# XMC4700 register map
Vendor: Infineon; File version: 1.0.3 (Reference Manual v1.0)
CPU: CM4 r2p0, little endian, MPU, FPU, 6 interrupt priority bits
Registers are 32-bit, read-write, reset 0x0 unless marked. A register's access mark holds for its fields unless they carry their own. Offsets are from the block's base; [hi:lo] are bit positions; {n}, {i} and the like mark numbered series; 'fields as' and 'values as' point back to an identical list.

## USIC0_CH0 — Universal Serial Interface Controller 0
Base 0x40030000
Same registers: USIC0_CH1 0x40030200, USIC1_CH0 0x48020000, USIC1_CH1 0x48020200, USIC2_CH0 0x48024000, USIC2_CH1 0x48024200
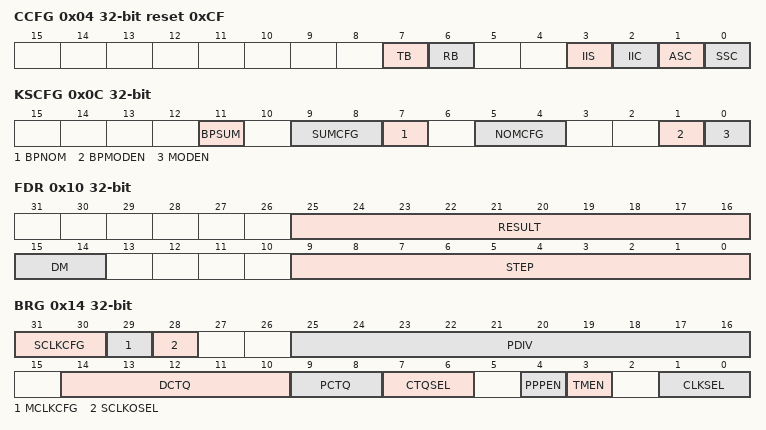
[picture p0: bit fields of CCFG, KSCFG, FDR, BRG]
0x04 CCFG ro reset 0xCF — Channel Configuration Register
  [7] TB — Transmit FIFO Buffer Available
    0=A transmit FIFO buffer is not available; 1=A transmit FIFO buffer is available
  [6] RB — Receive FIFO Buffer Available
    0=A receive FIFO buffer is not available; 1=A receive FIFO buffer is available
  [3] IIS — IIS Protocol Available
    0=The IIS protocol is not available; 1=The IIS protocol is available
  [2] IIC — IIC Protocol Available
    0=The IIC protocol is not available; 1=The IIC protocol is available
  [1] ASC — ASC Protocol Available
    0=The ASC protocol is not available; 1=The ASC protocol is available
  [0] SSC — SSC Protocol Available
    0=The SSC protocol is not available; 1=The SSC protocol is available
0x0C KSCFG access per field — Kernel State Configuration Register
  [11] BPSUM wo — Bit Protection for SUMCFG
    0=SUMCFG is not changed; 1=SUMCFG is updated with the written value
  [9:8] SUMCFG rw — Suspend Mode Configuration
  [7] BPNOM wo — Bit Protection for NOMCFG
    0=NOMCFG is not changed; 1=NOMCFG is updated with the written value
  [5:4] NOMCFG rw — Normal Operation Mode Configuration
    0=Run mode 0 is selected; 1=Run mode 1 is selected; 2=Stop mode 0 is selected; 3=Stop mode 1 is selected
  [1] BPMODEN wo — Bit Protection for MODEN
    0=MODEN is not changed; 1=MODEN is updated with the written value
  [0] MODEN rw — Module Enable
    0=The module is switched off immediately (without respecting a stop condition). It does not react on mode control actions and the module clock is switched off. The module does not react on read accesses and ignores write accesses (except to KSCFG).; 1=The module is switched on and can operate. After writing 1 to MODEN, it is recommended to read register KSCFG to avoid pipeline effects in the control block before accessing other Service Request Processing registers.
0x10 FDR access per field — Fractional Divider Register
  [25:16] RESULT ro — Result Value
  [15:14] DM rw — Divider Mode
    0=The divider is switched off, fFD = 0; 1=Normal divider mode selected; 2=Fractional divider mode selected; 3=The divider is switched off, fFD = 0
  [9:0] STEP rw — Step Value
0x14 BRG — Baud Rate Generator Register
  [31:30] SCLKCFG — Shift Clock Output Configuration
    0=The passive level is 0 and the delay is disabled; 1=The passive level is 1 and the delay is disabled; 2=The passive level is 0 and the delay is enabled; 3=The passive level is 1 and the delay is enabled
  [29] MCLKCFG — Master Clock Configuration
    0=The passive level is 0; 1=The passive level is 1
  [28] SCLKOSEL — Shift Clock Output Select
    0=SCLK from the baud rate generator is selected as the SCLKOUT input source; 1=The transmit shift clock from DX1 input stage is selected as the SCLKOUT input source
  [25:16] PDIV — Divider Mode: Divider Factor to Generate fPDIV
  [14:10] DCTQ — Denominator for Time Quanta Counter
  [9:8] PCTQ — Pre-Divider for Time Quanta Counter
  [7:6] CTQSEL — Input Selection for CTQ
    0=fCTQIN = fPDIV; 1=fCTQIN = fPPP; 2=fCTQIN = fSCLK; 3=fCTQIN = fMCLK
  [4] PPPEN — Enable 2:1 Divider for fPPP
    0=The 2:1 divider for fPPP is disabled. fPPP = fPIN; 1=The 2:1 divider for fPPP is enabled. fPPP = fMCLK = fPIN / 2.
  [3] TMEN — Timing Measurement Enable
    0=Timing measurement is disabled: The trigger signals DX0T and DX1T are ignored; 1=Timing measurement is enabled: The 10-bit counter is incremented by 1 with fPPP and stops counting when reaching its maximum value. If one of the trigger signals DX0T or DX1T become active, the counter value is captured into bit field CTV, the counter is cleared and a transmit shift event is generated.
  [1:0] CLKSEL — Clock Selection
    0=The fractional divider frequency fFD is selected; 2=The trigger signal DX1T defines fPIN. Signal MCLK toggles with fPIN.; 3=Signal MCLK corresponds to the DX1S signal and the frequency fPIN is derived from the rising edges of DX1S
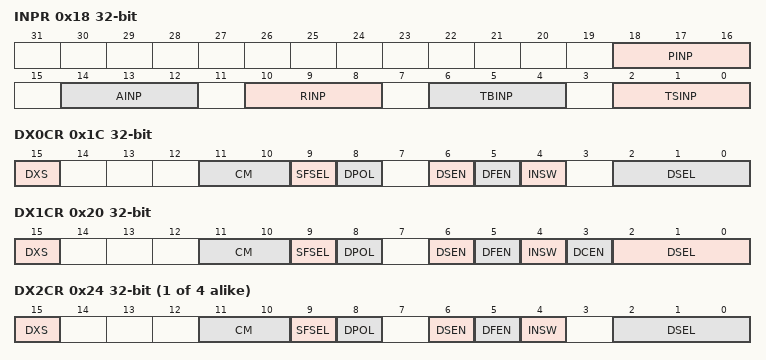
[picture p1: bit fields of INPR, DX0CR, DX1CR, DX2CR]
0x18 INPR — Interrupt Node Pointer Register
  [18:16] PINP — Transmit Shift Interrupt Node Pointer
  [14:12] AINP — Alternative Receive Interrupt Node Pointer
  [10:8] RINP — Receive Interrupt Node Pointer
  [6:4] TBINP — Transmit Buffer Interrupt Node Pointer
  [2:0] TSINP — Transmit Shift Interrupt Node Pointer
    {v}=Output SR{v} becomes activated (v=0..5)
0x1C DX0CR access per field — Input Control Register 0
  [15] DXS ro — Synchronized Data Value
    0=The current value of DXnS is 0; 1=The current value of DXnS is 1
  [11:10] CM rw — Combination Mode
    0=The trigger activation is disabled; 1=A rising edge activates DXnT; 2=A falling edge activates DXnT; 3=Both edges activate DXnT
  [9] SFSEL rw — Sampling Frequency Selection
    0=The sampling frequency is fPB; 1=The sampling frequency is fFD
  [8] DPOL rw — Data Polarity for DXn
    0=The input signal is not inverted; 1=The input signal is inverted
  [6] DSEN rw — Data Synchronization Enable
    0=The un-synchronized signal can be taken as input for the data shift unit; 1=The synchronized signal can be taken as input for the data shift unit
  [5] DFEN rw — Digital Filter Enable
    0=The input signal is not digitally filtered; 1=The input signal is digitally filtered
  [4] INSW rw — Input Switch
    0=The input of the data shift unit is controlled by the protocol pre-processor; 1=The input of the data shift unit is connected to the selected data input line. This setting is used if the signals are directly derived from an input pin without treatment by the protocol pre-processor.
  [2:0] DSEL rw — Data Selection for Input Signal
    0=The data input DXnA is selected; 1=The data input DXnB is selected; 2=The data input DXnC is selected; 3=The data input DXnD is selected; 4=The data input DXnE is selected; 5=The data input DXnF is selected; 6=The data input DXnG is selected; 7=The data input is always 1
0x20 DX1CR access per field — Input Control Register 1
  [15] DXS ro — Synchronized Data Value
    0=The current value of DX1S is 0; 1=The current value of DX1S is 1
  [11:10] CM rw — Combination Mode
    0=The trigger activation is disabled; 1=A rising edge activates DX1T; 2=A falling edge activates DX1T; 3=Both edges activate DX1T
  [9] SFSEL rw — Sampling Frequency Selection
    values as DX0CR.SFSEL
  [8] DPOL rw — Data Polarity for DXn
    values as DX0CR.DPOL
  [6] DSEN rw — Data Synchronization Enable
    values as DX0CR.DSEN
  [5] DFEN rw — Digital Filter Enable
    values as DX0CR.DFEN
  [4] INSW rw — Input Switch
    values as DX0CR.INSW
  [3] DCEN rw — Delay Compensation Enable
    0=The receive shift clock is dependent on INSW selection; 1=The receive shift clock is connected to the selected data input line. This setting is used if delay compensation is required in SSC and IIS protocols, else DCEN should always be 0.
  [2:0] DSEL rw — Data Selection for Input Signal
    0=The data input DX1A is selected; 1=The data input DX1B is selected; 2=The data input DX1C is selected; 3=The data input DX1D is selected; 4=The data input DX1E is selected; 5=The data input DX1F is selected; 6=The data input DX1G is selected; 7=The data input is always 1
{0x1C+4i} DX{i}CR access per field (i=2..5) — Input Control Register {i}
  fields as DX0CR
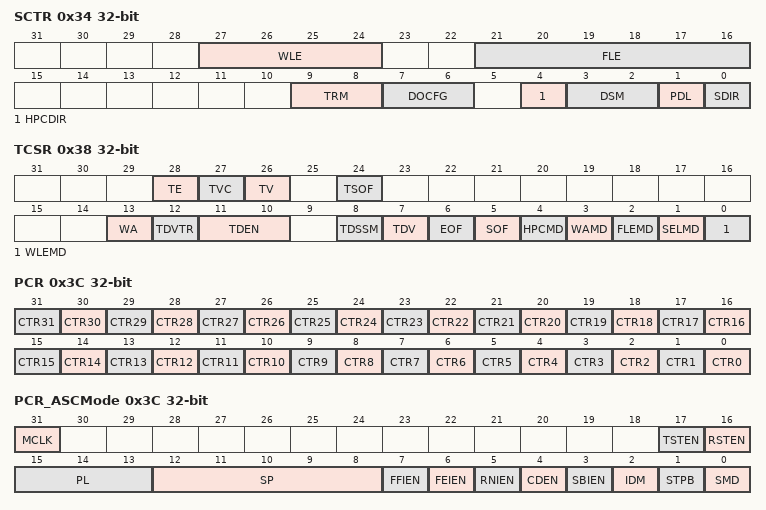
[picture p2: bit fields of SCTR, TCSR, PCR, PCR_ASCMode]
0x34 SCTR — Shift Control Register
  [27:24] WLE — Word Length
    0=The data word contains 1 data bit located at bit position 0; 1=The data word contains 2 data bits located at bit positions [1:0]; 14=The data word contains 15 data bits located at bit positions [14:0]; 15=The data word contains 16 data bits located at bit positions [15:0]
  [21:16] FLE — Frame Length
  [9:8] TRM — Transmission Mode
    0=The shift control signal is considered as inactive and data frame transfers are not possible; 1=The shift control signal is considered active if it is at 1-level. This is the setting to be programmed to allow data transfers.; 2=The shift control signal is considered active if it is at 0-level. It is recommended to avoid this setting and to use the inversion in the DX2 stage in case of a low-active signal.; 3=The shift control signal is considered active without referring to the actual signal level. Data frame transfer is possible after each edge of the signal.
  [7:6] DOCFG — Data Output Configuration
    0=DOUTx = shift data value; 1=DOUTx = inverted shift data value
  [4] HPCDIR — Port Control Direction
    0=The pin(s) with hardware pin control enabled are selected to be in input mode; 1=The pin(s) with hardware pin control enabled are selected to be in output mode
  [3:2] DSM — Data Shift Mode
    0=Receive and transmit data is shifted in and out one bit at a time through DX0 and DOUT0; 2=Receive and transmit data is shifted in and out two bits at a time through two input stages (DX0 and DX3) and DOUT[1:0] respectively; 3=Receive and transmit data is shifted in and out four bits at a time through four input stages (DX0, DX[5:3]) and DOUT[3:0] respectively
  [1] PDL — Passive Data Level
    0=The passive data level is 0; 1=The passive data level is 1
  [0] SDIR — Shift Direction
    0=Shift LSB first. The first data bit of a data word is located at bit position 0.; 1=Shift MSB first. The first data bit of a data word is located at the bit position given by bit field SCTR.WLE.
0x38 TCSR access per field — Transmit Control/Status Register
  [28] TE ro — Trigger Event
    0=The trigger event has not yet been detected. A transmission of the data word in TBUF can not be started.; 1=The trigger event has been detected (or the trigger mechanism is switched off) and a transmission of the data word in TBUF can not be started
  [27] TVC ro — Transmission Valid Cumulated
    0=Since TVC has been set, at least one data buffer underflow condition has occurred; 1=Since TVC has been set, no data buffer underflow condition has occurred
  [26] TV ro — Transmission Valid
    0=The latest start of a data word transmission has taken place while no valid data was available. As a result, the transmission of a data words with passive level (SCTR.PDL) has been started.; 1=The latest start of a data word transmission has taken place with valid data from TBUF
  [24] TSOF ro — Transmitted Start Of Frame
    0=The latest data word transmission has not been started for the first word of a data frame; 1=The latest data word transmission has been started for the first word of a data frame
  [13] WA rw — Word Address
    0=The data word in TBUF will be transmitted after a falling edge of WA has been detected (referring to PSR.WA); 1=The data word in TBUF will be transmitted after a rising edge of WA has been detected (referring to PSR.WA)
  [12] TDVTR rw — TBUF Data Valid Trigger
    0=Bit TCSR.TE is permanently set; 1=Bit TCSR.TE is set if DX2T becomes active while TDV = 1
  [11:10] TDEN rw — TBUF Data Enable
    0=A transmission start of the data word in TBUF is disabled. If a transmission is started, the passive data level is sent out.; 1=A transmission of the data word in TBUF can be started if TDV = 1; 2=A transmission of the data word in TBUF can be started if TDV = 1 while DX2S = 0; 3=A transmission of the data word in TBUF can be started if TDV = 1 while DX2S = 1
  [8] TDSSM rw — TBUF Data Single Shot Mode
    0=The data word in TBUF is not considered as invalid after it has been loaded into the transmit shift register. The loading of the TBUF data into the shift register does not clear TDV.; 1=The data word in TBUF is considered as invalid after it has been loaded into the shift register. In ASC and IIC mode, TDV is cleared with the TBI event, whereas in SSC and IIS mode, it is cleared with the RSI event. TDSSM = 1 has to be programmed if an optional data buffer is used.
  [7] TDV ro — Transmit Data Valid
    0=The data word in TBUF is not valid for transmission; 1=The data word in TBUF is valid for transmission and a transmission start is possible. New data should not be written to a TBUFx input location while TDV = 1.
  [6] EOF rw — End Of Frame
    0=The data word in TBUF is not considered as last word of an SSC frame; 1=The data word in TBUF is considered as last word of an SSC frame
  [5] SOF rw — Start Of Frame
    0=The data word in TBUF is not considered as first word of a frame; 1=The data word in TBUF is considered as first word of a frame. A currently running frame is finished and MSLS becomes deactivated (respecting the programmed delays).
  [4] HPCMD rw — Hardware Port Control Mode
    0=The automatic update of bits SCTR.DSM and SCTR.HPCDIR is disabled; 1=The automatic update of bits SCTR.DSM and SCTR.HPCDIR is enabled
  [3] WAMD rw — WA Mode
    0=The automatic update of bit WA is disabled; 1=The automatic update of bit WA is enabled
  [2] FLEMD rw — FLE Mode
    0=The automatic update of FLE is disabled; 1=The automatic update of FLE is enabled
  [1] SELMD rw — Select Mode
    0=The automatic update of PCR.CTR[23:16] is disabled; 1=The automatic update of PCR.CTR[23:16] is disabled
  [0] WLEMD rw — WLE Mode
    0=The automatic update of SCTR.WLE and TCSR.EOF is disabled; 1=The automatic update of SCTR.WLE and TCSR.EOF is enabled
0x3C PCR — Protocol Control Register
  [n] CTR{n} (n=0..31) — Protocol Control Bit {n}
0x3C PCR_ASCMode (alternate view of PCR) — Protocol Control Register [ASC Mode]
  [31] MCLK — Master Clock Enable
    0=The MCLK generation is disabled and the MCLK signal is 0; 1=The MCLK generation is enabled
  [17] TSTEN — Transmitter Status Enable
    0=Flag PSR[9] is not modified depending on the transmitter status; 1=Flag PSR[9] is set during the complete transmission of a frame
  [16] RSTEN — Receiver Status Enable
    0=Flag PSR[9] is not modified depending on the receiver status; 1=Flag PSR[9] is set during the complete reception of a frame
  [15:13] PL — Pulse Length
    0=The pulse length is equal to the bit length (no shortened 0); 1=The pulse length of a 0 bit is 2 time quanta; 2=The pulse length of a 0 bit is 3 time quanta; 7=The pulse length of a 0 bit is 8 time quanta
  [12:8] SP — Sample Point
  [7] FFIEN — Frame Finished Interrupt Enable
    0=The interrupt generation is disabled; 1=The interrupt generation is enabled
  [6] FEIEN — Format Error Interrupt Enable
    values as FFIEN
  [5] RNIEN — Receiver Noise Detection Interrupt Enable
    values as FFIEN
  [4] CDEN — Collision Detection Enable
    0=The collision detection is disabled; 1=If a collision is detected, the transmitter stops its data transmission, outputs a 1, sets bit PSR.COL and generates a protocol interrupt. In order to allow data transmission again, PSR.COL has to be cleared by software.
  [3] SBIEN — Synchronization Break Interrupt Enable
    values as FFIEN
  [2] IDM — Idle Detection Mode
    0=The bus idle detection is switched off and bits PSR.TXIDLE and PSR.RXIDLE are set automatically to enable data transfers without checking the inputs before; 1=The bus is considered as idle after a number of consecutive passive bit times defined by SCTR.FLE plus 2 (in the case without parity bit) or plus 3 (in the case with parity bit)
  [1] STPB — Stop Bits
    0=The number of stop bits is 1; 1=The number of stop bits is 2
  [0] SMD — Sample Mode
    0=Only one sample is taken per bit time. The current input value is sampled.; 1=Three samples are taken per bit time and a majority decision is made
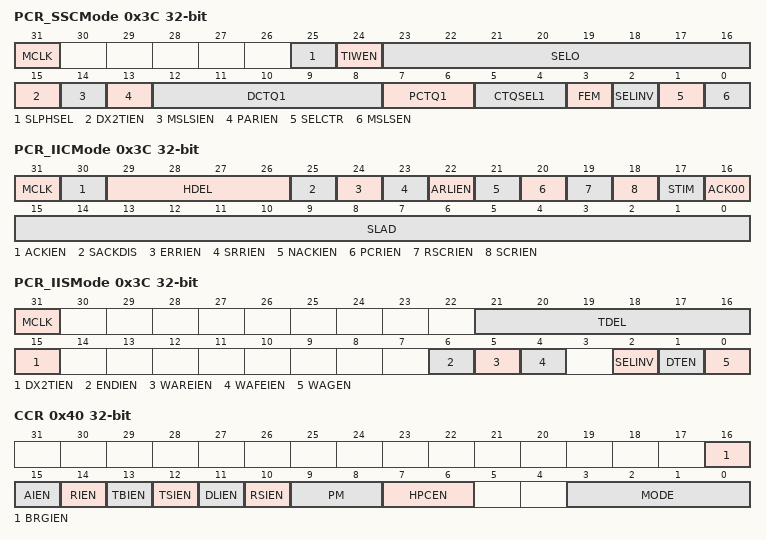
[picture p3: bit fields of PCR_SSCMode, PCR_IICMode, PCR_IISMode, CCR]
0x3C PCR_SSCMode (alternate view of PCR) — Protocol Control Register [SSC Mode]
  [31] MCLK — Master Clock Enable
    0=The MCLK generation is disabled and output MCLK = 0; 1=The MCLK generation is enabled
  [25] SLPHSEL — Slave Mode Clock Phase Select
    0=Data bits are shifted out with the leading edge of the shift clock signal and latched in with the trailing edge; 1=The first data bit is shifted out when the data shift unit receives a low to high transition from the DX2 stage. Subsequent bits are shifted out with the trailing edge of the shift clock signal. Data bits are always latched in with the leading edge.
  [24] TIWEN — Enable Inter-Word Delay Tiw
    0=No delay between data words of the same frame; 1=The inter-word delay Tiw is enabled and introduced between data words of the same frame
  [23:16] SELO — Select Output
    0=The corresponding SELOx line cannot be activated; 1=The corresponding SELOx line can be activated (according to the mode selected by SELCTR)
  [15] DX2TIEN — DX2T Interrupt Enable
    0=A protocol interrupt is not generated if DX2T is activated; 1=A protocol interrupt is generated if DX2T is activated
  [14] MSLSIEN — MSLS Interrupt Enable
    0=A protocol interrupt is not generated if a change of signal MSLS is detected; 1=A protocol interrupt is generated if a change of signal MSLS is detected
  [13] PARIEN — Parity Error Interrupt Enable
    0=A protocol interrupt is not generated with the detection of a parity error; 1=A protocol interrupt is generated with the detection of a parity error
  [12:8] DCTQ1 — Divider Factor DCTQ1 for Tiw and Tnf
  [7:6] PCTQ1 — Divider Factor PCTQ1 for Tiw and Tnf
  [5:4] CTQSEL1 — Input Frequency Selection
    values as BRG.CTQSEL
  [3] FEM — Frame End Mode
    0=The current data frame is considered as finished when the last bit of a data word has been sent out and the transmit buffer TBUF does not contain new data (TDV = 0); 1=The MSLS signal is kept active also while no new data is available and no other end of frame condition is reached. In this case, the software can accept delays in delivering the data without automatic deactivation of MSLS in multi-word data frames.
  [2] SELINV — Select Inversion
    0=The SELO outputs have the same polarity as the MSLS signal (active high); 1=The SELO outputs have the inverted polarity to the MSLS signal (active low)
  [1] SELCTR — Select Control
    0=The coded select mode is enabled; 1=The direct select mode is enabled
  [0] MSLSEN — MSLS Enable
    0=The MSLS generation is disabled (MSLS = 0). This is the setting for SSC slave mode.; 1=The MSLS generation is enabled. This is the setting for SSC master mode.
0x3C PCR_IICMode (alternate view of PCR) — Protocol Control Register [IIC Mode]
  [31] MCLK — Master Clock Enable
    0=The MCLK generation is disabled and MCLK is 0; 1=The MCLK generation is enabled
  [30] ACKIEN — Acknowledge Interrupt Enable
    0=The acknowledge interrupt is disabled; 1=The acknowledge interrupt is enabled
  [29:26] HDEL — Hardware Delay
  [25] SACKDIS — Slave Acknowledge Disable
    0=The generation of an active slave acknowledge is enabled (slave acknowledge with 0 level = more bytes can be received); 1=The generation of an active slave acknowledge is disabled (slave acknowledge with 1 level = reception stopped)
  [24] ERRIEN — Error Interrupt Enable
    0=The error interrupt is disabled; 1=The error interrupt is enabled
  [23] SRRIEN — Slave Read Request Interrupt Enable
    0=The slave read request interrupt is disabled; 1=The slave read request interrupt is enabled
  [22] ARLIEN — Arbitration Lost Interrupt Enable
    0=The arbitration lost interrupt is disabled; 1=The arbitration lost interrupt is enabled
  [21] NACKIEN — Non-Acknowledge Interrupt Enable
    0=The non-acknowledge interrupt is disabled; 1=The non-acknowledge interrupt is enabled
  [20] PCRIEN — Stop Condition Received Interrupt Enable
    0=The stop condition interrupt is disabled; 1=The stop condition interrupt is enabled
  [19] RSCRIEN — Repeated Start Condition Received Interrupt Enable
    0=The repeated start condition interrupt is disabled; 1=The repeated start condition interrupt is enabled
  [18] SCRIEN — Start Condition Received Interrupt Enable
    0=The start condition interrupt is disabled; 1=The start condition interrupt is enabled
  [17] STIM — Symbol Timing
    0=A symbol contains 10 time quanta. The timing is adapted for standard mode (100 kBaud).; 1=A symbol contains 25 time quanta. The timing is adapted for fast mode (400 kBaud).
  [16] ACK00 — Acknowledge 00H
    0=The slave device is not sensitive to this address; 1=The slave device is sensitive to this address
  [15:0] SLAD — Slave Address
0x3C PCR_IISMode (alternate view of PCR) — Protocol Control Register [IIS Mode]
  [31] MCLK — Master Clock Enable
    values as PCR_IICMode.MCLK
  [21:16] TDEL — Transfer Delay
  [15] DX2TIEN — DX2T Interrupt Enable
    0=A protocol interrupt is not generated if DX2T is active; 1=A protocol interrupt is generated if DX2T is active
  [6] ENDIEN — END Interrupt Enable
    0=A protocol interrupt is not activated; 1=A protocol interrupt is activated
  [5] WAREIEN — WA Rising Edge Interrupt Enable
    0=A protocol interrupt is not activated if a rising edge of WA is generated; 1=A protocol interrupt is activated if a rising edge of WA is generated
  [4] WAFEIEN — WA Falling Edge Interrupt Enable
    0=A protocol interrupt is not activated if a falling edge of WA is generated; 1=A protocol interrupt is activated if a falling edge of WA is generated
  [2] SELINV — Select Inversion
    0=The SELOx outputs have the same polarity as the WA signal; 1=The SELOx outputs have the inverted polarity to the WA signal
  [1] DTEN — Data Transfers Enable
    0=The changes of the WA input signal are ignored and no transfers take place; 1=Transfers are enabled
  [0] WAGEN — WA Generation Enable
    0=The IIS can be used as slave. The generation of the word address signal is disabled. The output signal WA is 0. The MCLKO signal generation depends on PCR.MCLK.; 1=The IIS can be used as master. The generation of the word address signal is enabled. The signal starts with a 0 after being enabled. The generation of MCLK is enabled, independent of PCR.MCLK. After clearing WAGEN, the USIC module stops the generation of the WA signal within the next 4 WA periods.
0x40 CCR — Channel Control Register
  [16] BRGIEN — Baud Rate Generator Interrupt Enable
    0=The baud rate generator interrupt is disabled; 1=The baud rate generator interrupt is enabled. In case of a baud rate generator event, the service request output SRx indicated by INPR.PINP is activated.
  [15] AIEN — Alternative Receive Interrupt Enable
    0=The alternative receive interrupt is disabled; 1=The alternative receive interrupt is enabled. In case of an alternative receive event, the service request output SRx indicated by INPR.AINP is activated.
  [14] RIEN — Receive Interrupt Enable
    0=The receive interrupt is disabled; 1=The receive interrupt is enabled. In case of a receive event, the service request output SRx indicated by INPR.RINP is activated.
  [13] TBIEN — Transmit Buffer Interrupt Enable
    0=The transmit buffer interrupt is disabled; 1=The transmit buffer interrupt is enabled. In case of a transmit buffer event, the service request output SRx indicated by INPR.TBINP is activated.
  [12] TSIEN — Transmit Shift Interrupt Enable
    0=The transmit shift interrupt is disabled; 1=The transmit shift interrupt is enabled. In case of a transmit shift interrupt event, the service request output SRx indicated by INPR.TSINP is activated.
  [11] DLIEN — Data Lost Interrupt Enable
    0=The data lost interrupt is disabled; 1=The data lost interrupt is enabled. In case of a data lost event, the service request output SRx indicated by INPR.PINP is activated.
  [10] RSIEN — Receiver Start Interrupt Enable
    0=The receiver start interrupt is disabled; 1=The receiver start interrupt is enabled. In case of a receiver start event, the service request output SRx indicated by INPR.TBINP is activated.
  [9:8] PM — Parity Mode
    0=The parity generation is disabled; 2=Even parity is selected (parity bit = 1 on odd number of 1s in data, parity bit = 0 on even number of 1s in data); 3=Odd parity is selected (parity bit = 0 on odd number of 1s in data, parity bit = 1 on even number of 1s in data)
  [7:6] HPCEN — Hardware Port Control Enable
    0=The hardware port control is disabled; 1=The hardware port control is enabled for DX0 and DOUT0; 2=The hardware port control is enabled for DX3, DX0 and DOUT[1:0]; 3=The hardware port control is enabled for DX0, DX[5:3] and DOUT[3:0]
  [3:0] MODE — Operating Mode
    0=The USIC channel is disabled. All protocol-related state machines are set to an idle state.; 1=The SSC (SPI) protocol is selected; 2=The ASC (SCI, UART) protocol is selected; 3=The IIS protocol is selected; 4=The IIC protocol is selected
0x44 CMTR — Capture Mode Timer Register
  [9:0] CTV — Captured Timer Value
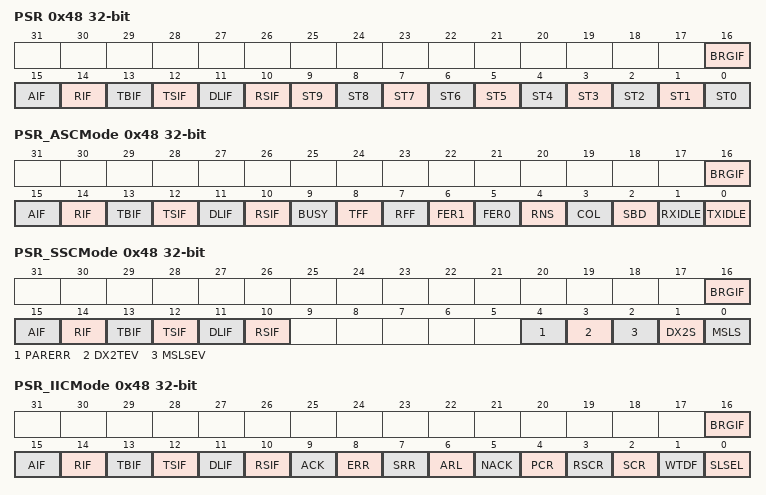
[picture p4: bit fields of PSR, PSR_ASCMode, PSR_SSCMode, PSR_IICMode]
0x48 PSR — Protocol Status Register
  [16] BRGIF — Baud Rate Generator Indication Flag
    0=A baud rate generator event has not occurred; 1=A baud rate generator event has occurred
  [15] AIF — Alternative Receive Indication Flag
    0=An alternative receive event has not occurred; 1=An alternative receive event has occurred
  [14] RIF — Receive Indication Flag
    0=A receive event has not occurred; 1=A receive event has occurred
  [13] TBIF — Transmit Buffer Indication Flag
    0=A transmit buffer event has not occurred; 1=A transmit buffer event has occurred
  [12] TSIF — Transmit Shift Indication Flag
    0=A transmit shift event has not occurred; 1=A transmit shift event has occurred
  [11] DLIF — Data Lost Indication Flag
    0=A data lost event has not occurred; 1=A data lost event has occurred
  [10] RSIF — Receiver Start Indication Flag
    0=A receiver start event has not occurred; 1=A receiver start event has occurred
  [n] ST{n} (n=0..9) — Protocol Status Flag {n}
0x48 PSR_ASCMode access per field (alternate view of PSR) — Protocol Status Register [ASC Mode]
  [16] BRGIF rw — Baud Rate Generator Indication Flag
    values as PSR.BRGIF
  [15] AIF rw — Alternative Receive Indication Flag
    values as PSR.AIF
  [14] RIF rw — Receive Indication Flag
    values as PSR.RIF
  [13] TBIF rw — Transmit Buffer Indication Flag
    values as PSR.TBIF
  [12] TSIF rw — Transmit Shift Indication Flag
    values as PSR.TSIF
  [11] DLIF rw — Data Lost Indication Flag
    values as PSR.DLIF
  [10] RSIF rw — Receiver Start Indication Flag
    values as PSR.RSIF
  [9] BUSY ro — Transfer Status BUSY
    0=A data transfer does not take place; 1=A data transfer currently takes place
  [8] TFF rw — Transmitter Frame Finished
    0=The transmitter frame is not yet finished; 1=The transmitter frame is finished
  [7] RFF rw — Receive Frame Finished
    0=The received frame is not yet finished; 1=The received frame is finished
  [6] FER1 rw — Format Error in Stop Bit 1
    0=A format error 1 has not been detected; 1=A format error 1 has been detected
  [5] FER0 rw — Format Error in Stop Bit 0
    0=A format error 0 has not been detected; 1=A format error 0 has been detected
  [4] RNS rw — Receiver Noise Detected
    0=Receiver noise has not been detected; 1=Receiver noise has been detected
  [3] COL rw — Collision Detected
    0=A collision has not yet been detected and frame transmission is possible; 1=A collision has been detected and frame transmission is not possible
  [2] SBD rw — Synchronization Break Detected
    0=A synchronization break has not yet been detected; 1=A synchronization break has been detected
  [1] RXIDLE rw — Reception Idle
    0=The receiver line has not yet been idle; 1=The receiver line has been idle and frame reception is possible
  [0] TXIDLE rw — Transmission Idle
    0=The transmitter line has not yet been idle; 1=The transmitter line has been idle and frame transmission is possible
0x48 PSR_SSCMode (alternate view of PSR) — Protocol Status Register [SSC Mode]
  [16] BRGIF — Baud Rate Generator Indication Flag
    values as PSR.BRGIF
  [15] AIF — Alternative Receive Indication Flag
    values as PSR.AIF
  [14] RIF — Receive Indication Flag
    values as PSR.RIF
  [13] TBIF — Transmit Buffer Indication Flag
    values as PSR.TBIF
  [12] TSIF — Transmit Shift Indication Flag
    values as PSR.TSIF
  [11] DLIF — Data Lost Indication Flag
    values as PSR.DLIF
  [10] RSIF — Receiver Start Indication Flag
    values as PSR.RSIF
  [4] PARERR — Parity Error Event Detected
    0=A parity error event has not been activated; 1=A parity error event has been activated
  [3] DX2TEV — DX2T Event Detected
    0=The DX2T signal has not been activated; 1=The DX2T signal has been activated
  [2] MSLSEV — MSLS Event Detected
    0=The MSLS signal has not changed its state; 1=The MSLS signal has changed its state
  [1] DX2S — DX2S Status
    0=DX2S is 0; 1=DX2S is 1
  [0] MSLS — MSLS Status
    0=The internal signal MSLS is inactive (0); 1=The internal signal MSLS is active (1)
0x48 PSR_IICMode (alternate view of PSR) — Protocol Status Register [IIC Mode]
  [16] BRGIF — Baud Rate Generator Indication Flag
    values as PSR.BRGIF
  [15] AIF — Alternative Receive Indication Flag
    values as PSR.AIF
  [14] RIF — Receive Indication Flag
    values as PSR.RIF
  [13] TBIF — Transmit Buffer Indication Flag
    values as PSR.TBIF
  [12] TSIF — Transmit Shift Indication Flag
    values as PSR.TSIF
  [11] DLIF — Data Lost Indication Flag
    values as PSR.DLIF
  [10] RSIF — Receiver Start Indication Flag
    values as PSR.RSIF
  [9] ACK — Acknowledge Received
    0=An acknowledge has not been received; 1=An acknowledge has been received
  [8] ERR — Error
    0=An IIC error has not been detected; 1=An IIC error has been detected
  [7] SRR — Slave Read Request
    0=A slave read request has not been detected; 1=A slave read request has been detected
  [6] ARL — Arbitration Lost
    0=An arbitration has not been lost; 1=An arbitration has been lost
  [5] NACK — Non-Acknowledge Received
    0=A non-acknowledge has not been received; 1=A non-acknowledge has been received
  [4] PCR — Stop Condition Received
    0=A stop condition has not yet been detected; 1=A stop condition has been detected
  [3] RSCR — Repeated Start Condition Received
    0=A repeated start condition has not yet been detected; 1=A repeated start condition has been detected
  [2] SCR — Start Condition Received
    0=A start condition has not yet been detected; 1=A start condition has been detected
  [1] WTDF — Wrong TDF Code Found
    0=A wrong TDF code has not been found; 1=A wrong TDF code has been found
  [0] SLSEL — Slave Select
    0=The device is not selected as slave; 1=The device is selected as slave
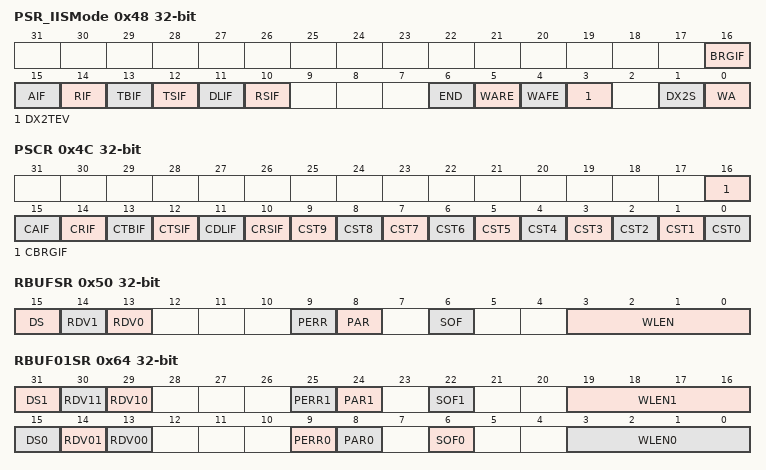
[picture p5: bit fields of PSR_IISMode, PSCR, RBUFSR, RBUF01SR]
0x48 PSR_IISMode (alternate view of PSR) — Protocol Status Register [IIS Mode]
  [16] BRGIF — Baud Rate Generator Indication Flag
    values as PSR.BRGIF
  [15] AIF — Alternative Receive Indication Flag
    values as PSR.AIF
  [14] RIF — Receive Indication Flag
    values as PSR.RIF
  [13] TBIF — Transmit Buffer Indication Flag
    values as PSR.TBIF
  [12] TSIF — Transmit Shift Indication Flag
    values as PSR.TSIF
  [11] DLIF — Data Lost Indication Flag
    values as PSR.DLIF
  [10] RSIF — Receiver Start Indication Flag
    values as PSR.RSIF
  [6] END — WA Generation End
    0=The WA generation has not yet ended (if it is running and WAGEN has been cleared); 1=The WA generation has ended (if it has been running)
  [5] WARE — WA Rising Edge Event
    0=A WA rising edge has not been generated; 1=A WA rising edge has been generated
  [4] WAFE — WA Falling Edge Event
    0=A WA falling edge has not been generated; 1=A WA falling edge has been generated
  [3] DX2TEV — DX2T Event Detected
    values as PSR_SSCMode.DX2TEV
  [1] DX2S — DX2S Status
    0=DX2S is 0; 1=DX2S is 1
  [0] WA — Word Address
    0=WA has been sampled 0; 1=WA has been sampled 1
0x4C PSCR wo — Protocol Status Clear Register
  [16] CBRGIF — Clear Baud Rate Generator Indication Flag
    0=No action; 1=Flag PSR.BRGIF is cleared
  [15] CAIF — Clear Alternative Receive Indication Flag
    0=No action; 1=Flag PSR.AIF is cleared
  [14] CRIF — Clear Receive Indication Flag
    0=No action; 1=Flag PSR.RIF is cleared
  [13] CTBIF — Clear Transmit Buffer Indication Flag
    0=No action; 1=Flag PSR.TBIF is cleared
  [12] CTSIF — Clear Transmit Shift Indication Flag
    0=No action; 1=Flag PSR.TSIF is cleared
  [11] CDLIF — Clear Data Lost Indication Flag
    0=No action; 1=Flag PSR.DLIF is cleared
  [10] CRSIF — Clear Receiver Start Indication Flag
    0=No action; 1=Flag PSR.RSIF is cleared
  [n] CST{n} (n=0..9) — Clear Status Flag {n} in PSR
    0=No action; 1=Flag PSR.STx is cleared
0x50 RBUFSR ro — Receiver Buffer Status Register
  [15] DS — Data Source of RBUF or RBUFD
  [14] RDV1 — Receive Data Valid in RBUF or RBUFD
  [13] RDV0 — Receive Data Valid in RBUF or RBUFD
  [9] PERR — Protocol-related Error in RBUF or RBUFD
  [8] PAR — Protocol-Related Argument in RBUF or RBUFD
  [6] SOF — Start of Frame in RBUF or RBUFD
  [3:0] WLEN — Received Data Word Length in RBUF or RBUFD
0x54 RBUF ro read-has-side-effects — Receiver Buffer Register
  [15:0] DSR — Received Data
0x58 RBUFD ro — Receiver Buffer Register for Debugger
  [15:0] DSR — Data from Shift Register
0x5C RBUF0 ro — Receiver Buffer Register 0
  [15:0] DSR0 — Data of Shift Registers 0[3:0]
0x60 RBUF1 ro — Receiver Buffer Register 1
  [15:0] DSR1 — Data of Shift Registers 1[3:0]
0x64 RBUF01SR ro — Receiver Buffer 01 Status Register
  [31] DS1 — Data Source
    0=The register RBUF contains the data of RBUF0 (same for associated status information); 1=The register RBUF contains the data of RBUF1 (same for associated status information)
  [30] RDV11 — Receive Data Valid in RBUF1
    0=Register RBUF1 does not contain data that has not yet been read out; 1=Register RBUF1 contains data that has not yet been read out
  [29] RDV10 — Receive Data Valid in RBUF0
    0=Register RBUF0 does not contain data that has not yet been read out; 1=Register RBUF0 contains data that has not yet been read out
  [25] PERR1 — Protocol-related Error in RBUF1
    0=The received protocol-related argument PAR matches the expected value. The reception of the data word sets bit PSR.RIF and can generate a receive interrupt.; 1=The received protocol-related argument PAR does not match the expected value. The reception of the data word sets bit PSR.AIF and can generate an alternative receive interrupt.
  [24] PAR1 — Protocol-Related Argument in RBUF1
  [22] SOF1 — Start of Frame in RBUF1
    0=The data in RBUF1 has not been the first data word of a data frame; 1=The data in RBUF1 has been the first data word of a data frame
  [19:16] WLEN1 — Received Data Word Length in RBUF1
    0=One bit has been received; 15=Sixteen bits have been received
  [15] DS0 — Data Source
    values as DS1
  [14] RDV01 — Receive Data Valid in RBUF1
    values as RDV11
  [13] RDV00 — Receive Data Valid in RBUF0
    values as RDV10
  [9] PERR0 — Protocol-related Error in RBUF0
    values as PERR1
  [8] PAR0 — Protocol-Related Argument in RBUF0
  [6] SOF0 — Start of Frame in RBUF0
    0=The data in RBUF0 has not been the first data word of a data frame; 1=The data in RBUF0 has been the first data word of a data frame
  [3:0] WLEN0 — Received Data Word Length in RBUF0
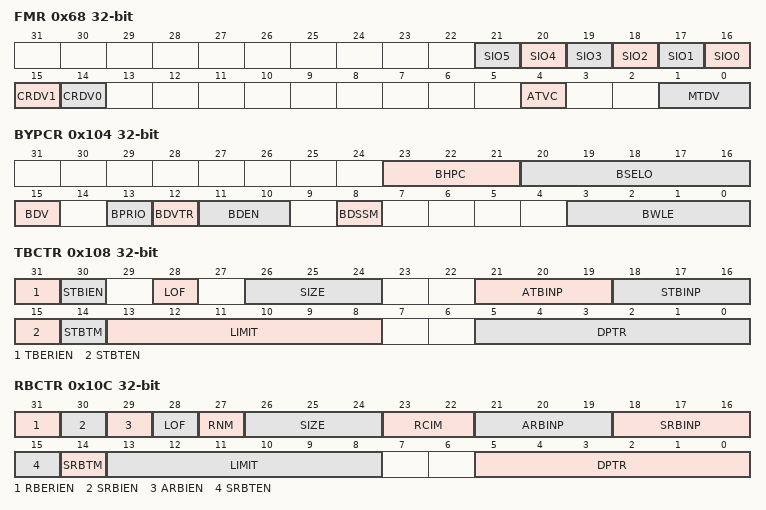
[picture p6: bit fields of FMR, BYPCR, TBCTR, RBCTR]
0x68 FMR wo — Flag Modification Register
  [n+16] SIO{n} (n=0..5) — Set Interrupt Output SRx
    0=No action; 1=The service request output SRx is activated
  [15] CRDV1 — Clear Bit RDV for RBUF1
    0=No action; 1=Bits RBUF01SR.RDV01 and RBUF01SR.RDV11 are cleared
  [14] CRDV0 — Clear Bits RDV for RBUF0
    0=No action; 1=Bits RBUF01SR.RDV00 and RBUF01SR.RDV10 are cleared
  [4] ATVC — Activate Bit TVC
    0=No action; 1=Bit TCSR.TVC is set
  [1:0] MTDV — Modify Transmit Data Valid
    0=No action; 1=Bit TDV is set, TE is unchanged; 2=Bits TDV and TE are cleared
{0x80+4i} TBUF[{i}] (i=0..31) — Transmit Buffer
  [15:0] TDATA — Transmit Data
0x100 BYP — Bypass Data Register
  [15:0] BDATA — Bypass Data
0x104 BYPCR access per field — Bypass Control Register
  [23:21] BHPC rw — Bypass Hardware Port Control
  [20:16] BSELO rw — Bypass Select Outputs
  [15] BDV ro — Bypass Data Valid
    0=The bypass data is not valid; 1=The bypass data is valid
  [13] BPRIO rw — Bypass Priority
    0=The transmit FIFO data has a higher priority than the bypass data; 1=The bypass data has a higher priority than the transmit FIFO data
  [12] BDVTR rw — Bypass Data Valid Trigger
    0=Bit BDV is not influenced by DX2T; 1=Bit BDV is set if DX2T is active
  [11:10] BDEN rw — Bypass Data Enable
    0=The transfer of bypass data is disabled; 1=The transfer of bypass data to TBUF is possible. Bypass data will be transferred to TBUF according to its priority if BDV = 1.; 2=Gated bypass data transfer is enabled. Bypass data will be transferred to TBUF according to its priority if BDV = 1 and while DX2S = 0.; 3=Gated bypass data transfer is enabled. Bypass data will be transferred to TBUF according to its priority if BDV = 1 and while DX2S = 1.
  [8] BDSSM rw — Bypass Data Single Shot Mode
    0=The bypass data is still considered as valid after it has been loaded into TBUF. The loading of the data into TBUF does not clear BDV.; 1=The bypass data is considered as invalid after it has been loaded into TBUF. The loading of the data into TBUF clears BDV.
  [3:0] BWLE rw — Bypass Word Length
0x108 TBCTR access per field — Transmitter Buffer Control Register
  [31] TBERIEN rw — Transmit Buffer Error Interrupt Enable
    0=The transmit buffer error interrupt generation is disabled; 1=The transmit buffer error interrupt generation is enabled
  [30] STBIEN rw — Standard Transmit Buffer Interrupt Enable
    0=The standard transmit buffer interrupt generation is disabled; 1=The standard transmit buffer interrupt generation is enabled
  [28] LOF rw — Buffer Event on Limit Overflow
    0=A standard transmit buffer event occurs when the filling level equals the limit value and gets lower due to transmission of a data word; 1=A standard transmit buffer interrupt event occurs when the filling level equals the limit value and gets bigger due to a write access to a data input location INx
  [26:24] SIZE rw — Buffer Size
    0=The FIFO mechanism is disabled. The buffer does not accept any request for data.; 1=The FIFO buffer contains 2 entries; 2=The FIFO buffer contains 4 entries; 3=The FIFO buffer contains 8 entries; 4=The FIFO buffer contains 16 entries; 5=The FIFO buffer contains 32 entries; 6=The FIFO buffer contains 64 entries
  [21:19] ATBINP rw — Alternative Transmit Buffer Interrupt Node Pointer
    {v}=Output SR{v} becomes activated (v=0..5)
  [18:16] STBINP rw — Standard Transmit Buffer Interrupt Node Pointer
    {v}=Output SR{v} becomes activated (v=0..5)
  [15] STBTEN rw — Standard Transmit Buffer Trigger Enable
    0=The standard transmit buffer event trigger through bit TRBSR.STBT is disabled; 1=The standard transmit buffer event trigger through bit TRBSR.STBT is enabled
  [14] STBTM rw — Standard Transmit Buffer Trigger Mode
    0=Trigger mode 0: While TRBSR.STBT=1, a standard buffer event will be generated whenever there is a data transfer to TBUF or data write to INx (depending on TBCTR.LOF setting). STBT is cleared when TRBSR.TBFLVL=TBCTR.LIMIT.; 1=Trigger mode 1: While TRBSR.STBT=1, a standard buffer event will be generated whenever there is a data transfer to TBUF or data write to INx (depending on TBCTR.LOF setting). STBT is cleared when TRBSR.TBFLVL=TBCTR.SIZE.
  [13:8] LIMIT rw — Limit For Interrupt Generation
  [5:0] DPTR wo — Data Pointer
0x10C RBCTR access per field — Receiver Buffer Control Register
  [31] RBERIEN rw — Receive Buffer Error Interrupt Enable
    0=The receive buffer error interrupt generation is disabled; 1=The receive buffer error interrupt generation is enabled
  [30] SRBIEN rw — Standard Receive Buffer Interrupt Enable
    0=The standard receive buffer interrupt generation is disabled; 1=The standard receive buffer interrupt generation is enabled
  [29] ARBIEN rw — Alternative Receive Buffer Interrupt Enable
    0=The alternative receive buffer interrupt generation is disabled; 1=The alternative receive buffer interrupt generation is enabled
  [28] LOF rw — Buffer Event on Limit Overflow
    0=A standard receive buffer event occurs when the filling level equals the limit value and gets lower due to a read access from OUTR; 1=A standard receive buffer event occurs when the filling level equals the limit value and gets bigger due to the reception of a new data word
  [27] RNM rw — Receiver Notification Mode
    0=Filling level mode: A standard receive buffer event occurs when the filling level equals the limit value and changes, either due to a read access from OUTR (LOF = 0) or due to a new received data word (LOF = 1); 1=RCI mode: A standard receive buffer event occurs when register OUTR is updated with a new value if the corresponding value in OUTR.RCI[4] = 0. If OUTR.RCI[4] = 1, an alternative receive buffer event occurs instead of the standard receive buffer event.
  [26:24] SIZE rw — Buffer Size
    values as TBCTR.SIZE
  [23:22] RCIM rw — Receiver Control Information Mode
    0=RCI[4] = PERR, RCI[3:0] = WLEN; 1=RCI[4] = SOF, RCI[3:0] = WLEN; 2=RCI[4] = 0, RCI[3:0] = WLEN; 3=RCI[4] = PERR, RCI[3] = PAR, RCI[2:1] = 00B, RCI[0] = SOF
  [21:19] ARBINP rw — Alternative Receive Buffer Interrupt Node Pointer
    {v}=Output SR{v} becomes activated (v=0..5)
  [18:16] SRBINP rw — Standard Receive Buffer Interrupt Node Pointer
    {v}=Output SR{v} becomes activated (v=0..5)
  [15] SRBTEN rw — Standard Receive Buffer Trigger Enable
    0=The standard receive buffer event trigger through bit TRBSR.SRBT is disabled; 1=The standard receive buffer event trigger through bit TRBSR.SRBT is enabled
  [14] SRBTM rw — Standard Receive Buffer Trigger Mode
    0=Trigger mode 0: While TRBSR.SRBT=1, a standard receive buffer event will be generated whenever there is a new data received or data read out (depending on RBCTR.LOF setting). SRBT is cleared when TRBSR.RBFLVL=RBCTR.LIMIT.; 1=Trigger mode 1: While TRBSR.SRBT=1, a standard receive buffer event will be generated whenever there is a new data received or data read out (depending on RBCTR.LOF setting). SRBT is cleared when TRBSR.RBFLVL=0.
  [13:8] LIMIT rw — Limit For Interrupt Generation
  [5:0] DPTR wo — Data Pointer
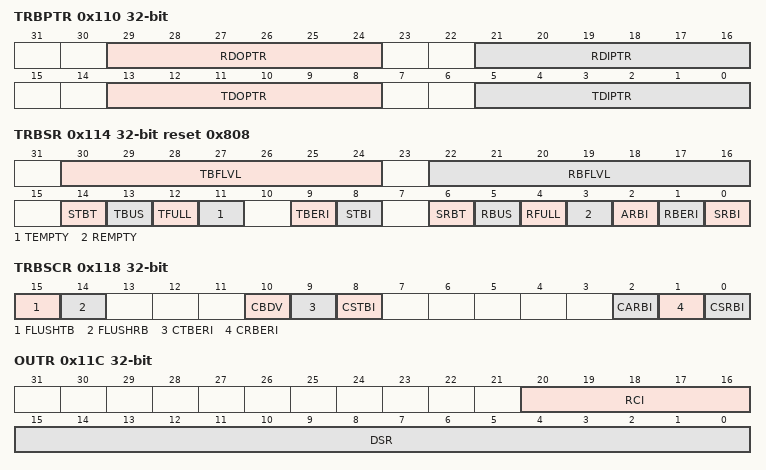
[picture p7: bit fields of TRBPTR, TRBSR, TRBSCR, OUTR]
0x110 TRBPTR ro — Transmit/Receive Buffer Pointer Register
  [29:24] RDOPTR — Receiver Data Output Pointer
  [21:16] RDIPTR — Receiver Data Input Pointer
  [13:8] TDOPTR — Transmitter Data Output Pointer
  [5:0] TDIPTR — Transmitter Data Input Pointer
0x114 TRBSR access per field reset 0x808 — Transmit/Receive Buffer Status Register
  [30:24] TBFLVL ro — Transmit Buffer Filling Level
  [22:16] RBFLVL ro — Receive Buffer Filling Level
  [14] STBT ro — Standard Transmit Buffer Event Trigger
    0=A standard transmit buffer event is not triggered using this bit; 1=A standard transmit buffer event is triggered using this bit
  [13] TBUS ro — Transmit Buffer Busy
    0=The transmit buffer information has been completely updated; 1=The FIFO memory update after write to INx is ongoing. A write to INx will be delayed. FIFO pointers from the previous INx write are not yet updated.
  [12] TFULL ro — Transmit Buffer Full
    0=The transmit buffer is not full; 1=The transmit buffer is full
  [11] TEMPTY ro — Transmit Buffer Empty
    0=The transmit buffer is not empty; 1=The transmit buffer is empty
  [9] TBERI rw — Transmit Buffer Error Event
    0=A transmit buffer error event has not been detected; 1=A transmit buffer error event has been detected
  [8] STBI rw — Standard Transmit Buffer Event
    0=A standard transmit buffer event has not been detected; 1=A standard transmit buffer event has been detected
  [6] SRBT ro — Standard Receive Buffer Event Trigger
    0=A standard receive buffer event is not triggered using this bit; 1=A standard receive buffer event is triggered using this bit
  [5] RBUS ro — Receive Buffer Busy
    0=The receive buffer information has been completely updated; 1=The OUTR update from the FIFO memory is ongoing. A read from OUTR will be delayed. FIFO pointers from the previous read are not yet updated.
  [4] RFULL ro — Receive Buffer Full
    0=The receive buffer is not full; 1=The receive buffer is full
  [3] REMPTY ro — Receive Buffer Empty
    0=The receive buffer is not empty; 1=The receive buffer is empty
  [2] ARBI rw — Alternative Receive Buffer Event
    0=An alternative receive buffer event has not been detected; 1=An alternative receive buffer event has been detected
  [1] RBERI rw — Receive Buffer Error Event
    0=A receive buffer error event has not been detected; 1=A receive buffer error event has been detected
  [0] SRBI rw — Standard Receive Buffer Event
    0=A standard receive buffer event has not been detected; 1=A standard receive buffer event has been detected
0x118 TRBSCR wo — Transmit/Receive Buffer Status Clear Register
  [15] FLUSHTB — Flush Transmit Buffer
    0=No effect; 1=The transmit FIFO buffer is cleared (filling level is cleared and output pointer is set to input pointer value). Should only be used while the FIFO buffer is not taking part in data traffic.
  [14] FLUSHRB — Flush Receive Buffer
    0=No effect; 1=The receive FIFO buffer is cleared (filling level is cleared and output pointer is set to input pointer value). Should only be used while the FIFO buffer is not taking part in data traffic.
  [10] CBDV — Clear Bypass Data Valid
    0=No effect; 1=Clear BYPCR.BDV
  [9] CTBERI — Clear Transmit Buffer Error Event
    0=No effect; 1=Clear TRBSR.TBERI
  [8] CSTBI — Clear Standard Transmit Buffer Event
    0=No effect; 1=Clear TRBSR.STBI
  [2] CARBI — Clear Alternative Receive Buffer Event
    0=No effect; 1=Clear TRBSR.ARBI
  [1] CRBERI — Clear Receive Buffer Error Event
    0=No effect; 1=Clear TRBSR.RBERI
  [0] CSRBI — Clear Standard Receive Buffer Event
    0=No effect; 1=Clear TRBSR.SRBI
0x11C OUTR ro read-has-side-effects — Receiver Buffer Output Register
  [20:16] RCI — Receiver Control Information
  [15:0] DSR — Received Data
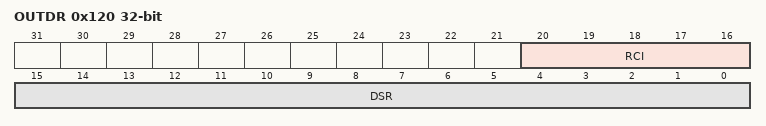
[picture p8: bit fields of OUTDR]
0x120 OUTDR ro — Receiver Buffer Output Register L for Debugger
  [20:16] RCI — Receive Control Information from Shift Register
  [15:0] DSR — Data from Shift Register
{0x180+4i} IN[{i}] (i=0..31) wo — Transmit FIFO Buffer
  [15:0] TDATA — Transmit Data
